# STM32MP21_CM33 register map
File version: 0.4
CPU: CM33 r0p1, little endian, MPU, FPU, vendor SysTick, 8 interrupt priority bits
Registers are 32-bit, read-write, reset 0x0 unless marked. A register's access mark holds for its fields unless they carry their own. Offsets are from the block's base; [hi:lo] are bit positions; {n}, {i} and the like mark numbered series; 'fields as' and 'values as' point back to an identical list.

## TIM12 — TIM12 address block description
Base 0x40060000
Same registers: TIM12_S 0x50060000
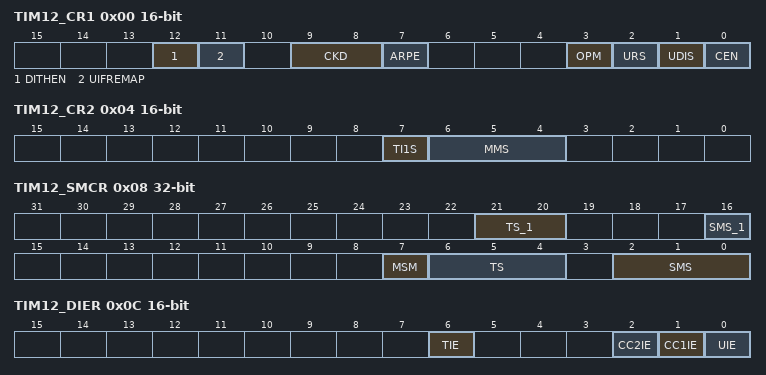
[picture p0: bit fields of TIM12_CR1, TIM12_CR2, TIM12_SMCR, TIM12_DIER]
0x00 TIM12_CR1 16-bit — TIM12 control register 1
  [12] DITHEN — Dithering enable
    0=Dithering disabled; 1=Dithering enabled
  [11] UIFREMAP — UIF status bit remapping
    0=No remapping; 1=Remapping enabled
  [9:8] CKD — Clock division
    0=tless thansub>DTSless than/sub> = tless thansub>tim_ker_ckless than/sub>; 1=tless thansub>DTSless than/sub> = 2 x tless thansub>tim_ker_ckless than/sub>; 2=tless thansub>DTSless than/sub> = 4 x tless thansub>tim_ker_ckless than/sub>
  [7] ARPE — Auto-reload preload enable
    0=TIMx_ARR register is not buffered; 1=TIMx_ARR register is buffered
  [3] OPM — One-pulse mode
    0=Counter is not stopped on the update event; 1=Counter stops counting on the next update event (clearing the CEN bit)
  [2] URS — Update request source
    0=Any of the following events generates an update interrupt if enabled; 1=Only counter overflow generates an update interrupt if enabled
  [1] UDIS — Update disable
    0=UEV enabled; 1=UEV disabled
  [0] CEN — Counter enable
    0=Counter disabled; 1=Counter enabled
0x04 TIM12_CR2 16-bit — TIM12 control register 2
  [7] TI1S — tim_ti1 selection
    0=The tim_ti1_in[15:0] multiplexer output is connected to tim_ti1 input; 1=The tim_ti1_in[15:0] and tim_ti2_in[15:0] multiplexers output are connected to the tim_ti1 input (XOR combination)
  [6:4] MMS — Master mode selection
    0=Reset - the UG bit from the TIMx_EGR register is used as trigger output (tim_trgo); 1=Enable - the Counter Enable signal CNT_EN is used as trigger output (tim_trgo); 2=Update - The update event is selected as trigger output (tim_trgo); 3=Compare Pulse - The trigger output send a positive pulse when the CC1IF flag is to be set (even if it was already high), as soon as a capture or a compare match occurred (tim_trgo); 4=Compare - tim_oc1refc signal is used as trigger output (tim_trgo); 5=Compare - tim_oc2refc signal is used as trigger output (tim_trgo)
0x08 TIM12_SMCR — TIM12 slave mode control register
  [21:20] TS_1 — TS[4:3]
  [16] SMS_1 — SMS[3]
  [7] MSM — Master/Slave mode
    0=No action; 1=The effect of an event on the trigger input (tim_trgi) is delayed to allow a perfect synchronization between the current timer and its slaves (through tim_trgo)
  [6:4] TS — TS[2:0]: Trigger selection
    {v}=Internal Trigger {v} (tim_itr{v}) (v=0..3); 4=tim_ti1 Edge Detector (tim_ti1f_ed); 5=Filtered Timer Input 1 (tim_ti1fp1); 6=Filtered Timer Input 2 (tim_ti2fp2)
  [2:0] SMS — SMS[2:0]: Slave mode selection
    0=Slave mode disabled - if CEN = 1' then the prescaler is clocked directly by the internal clock; 4=Reset Mode - Rising edge of the selected trigger input (tim_trgi) reinitializes the counter and generates an update of the registers; 5=Gated Mode - The counter clock is enabled when the trigger input (tim_trgi) is high; 6=Trigger Mode - The counter starts at a rising edge of the trigger tim_trgi (but it is not reset); 7=External Clock Mode 1 - Rising edges of the selected trigger (tim_trgi) clock the counter
0x0C TIM12_DIER 16-bit — TIM12 Interrupt enable register
  [6] TIE — Trigger interrupt enable
    0=Trigger interrupt disabled; 1=Trigger interrupt enabled
  [2] CC2IE — Capture/Compare 2 interrupt enable
    0=CC2 interrupt disabled; 1=CC2 interrupt enabled
  [1] CC1IE — Capture/Compare 1 interrupt enable
    0=CC1 interrupt disabled; 1=CC1 interrupt enabled
  [0] UIE — Update interrupt enable
    0=Update interrupt disabled; 1=Update interrupt enabled
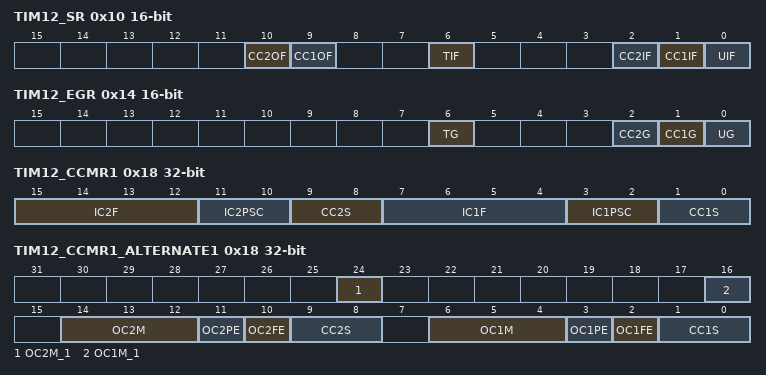
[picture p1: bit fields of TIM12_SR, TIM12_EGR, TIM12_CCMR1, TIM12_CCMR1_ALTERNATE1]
0x10 TIM12_SR 16-bit — TIM12 status register
  [10] CC2OF — Capture/compare 2 overcapture flag
  [9] CC1OF — Capture/Compare 1 overcapture flag
    0=No overcapture has been detected; 1=The counter value has been captured in TIMx_CCR1 register while CC1IF flag was already set
  [6] TIF — Trigger interrupt flag
    0=No trigger event occurred; 1=Trigger interrupt pending
  [2] CC2IF — Capture/Compare 2 interrupt flag
  [1] CC1IF — Capture/compare 1 interrupt flag
    0=No compare match / No input capture occurred; 1=A compare match or an input capture occurred
  [0] UIF — Update interrupt flag
    0=No update occurred; 1=Update interrupt pending
0x14 TIM12_EGR 16-bit wo — TIM12 event generation register
  [6] TG — Trigger generation
    0=No action; 1=The TIF flag is set in the TIMx_SR register
  [2] CC2G — Capture/compare 2 generation
  [1] CC1G — Capture/compare 1 generation
    0=No action; 1=A capture/compare event is generated on channel 1:
  [0] UG — Update generation
    0=No action; 1=Re-initializes the counter and generates an update of the registers
0x18 TIM12_CCMR1 — TIM12 capture/compare mode register 1
  [15:12] IC2F — Input capture 2 filter
  [11:10] IC2PSC — Input capture 2 prescaler
  [9:8] CC2S — Capture/compare 2 selection
    0=CC2 channel is configured as output; 1=CC2 channel is configured as input, IC2 is mapped on tim_ti2; 2=CC2 channel is configured as input, IC2 is mapped on tim_ti1; 3=CC2 channel is configured as input, IC2 is mapped on tim_trc
  [7:4] IC1F — Input capture 1 filter
    0=No filter, sampling is done at fless thansub>DTSless than/sub>; 1=fless thansub>SAMPLINGless than/sub>=fless thansub>tim_ker_ckless than/sub>, N=2; 2=fless thansub>SAMPLINGless than/sub>=fless thansub>tim_ker_ckless than/sub>, N=4; 3=fless thansub>SAMPLINGless than/sub>=fless thansub>tim_ker_ckless than/sub>, N=8; 4=fless thansub>SAMPLINGless than/sub>=fless thansub>DTSless than/sub>/2, N=6; 5=fless thansub>SAMPLINGless than/sub>=fless thansub>DTSless than/sub>/2, N=8; 6=fless thansub>SAMPLINGless than/sub>=fless thansub>DTSless than/sub>/4, N=6; 7=fless thansub>SAMPLINGless than/sub>=fless thansub>DTSless than/sub>/4, N=8; 8=fless thansub>SAMPLINGless than/sub>=fless thansub>DTSless than/sub>/8, N=6; 9=fless thansub>SAMPLINGless than/sub>=fless thansub>DTSless than/sub>/8, N=8; 10=fless thansub>SAMPLINGless than/sub>=fless thansub>DTSless than/sub>/16, N=5; 11=fless thansub>SAMPLINGless than/sub>=fless thansub>DTSless than/sub>/16, N=6; 12=fless thansub>SAMPLINGless than/sub>=fless thansub>DTSless than/sub>/16, N=8; 13=fless thansub>SAMPLINGless than/sub>=fless thansub>DTSless than/sub>/32, N=5; 14=fless thansub>SAMPLINGless than/sub>=fless thansub>DTSless than/sub>/32, N=6; 15=fless thansub>SAMPLINGless than/sub>=fless thansub>DTSless than/sub>/32, N=8
  [3:2] IC1PSC — Input capture 1 prescaler
    0=no prescaler, capture is done each time an edge is detected on the capture input; 1=capture is done once every 2 events; 2=capture is done once every 4 events; 3=capture is done once every 8 events
  [1:0] CC1S — Capture/Compare 1 selection
    0=CC1 channel is configured as output; 1=CC1 channel is configured as input, tim_ic1 is mapped on tim_ti1; 2=CC1 channel is configured as input, tim_ic1 is mapped on tim_ti2; 3=CC1 channel is configured as input, tim_ic1 is mapped on tim_trc
0x18 TIM12_CCMR1_ALTERNATE1 (alternate view of TIM12_CCMR1) — TIM12 capture/compare mode register 1
  [24] OC2M_1 — OC2M[3]
  [16] OC1M_1 — OC1M[3]
  [14:12] OC2M — OC2M[2:0]: Output compare 2 mode
  [11] OC2PE — Output compare 2 preload enable
  [10] OC2FE — Output compare 2 fast enable
  [9:8] CC2S — Capture/Compare 2 selection
    values as TIM12_CCMR1.CC2S
  [6:4] OC1M — OC1M[2:0]: Output compare 1 mode (refer to bit 16 for OC1M[3])
    0=Frozen - The comparison between the output compare register TIMx_CCR1 and the counter TIMx_CNT has no effect on the outputs; 1=Set channel 1 to active level on match; 2=Set channel 1 to inactive level on match; 3=Toggle - tim_oc1ref toggles when TIMx_CNT=TIMx_CCR1; 4=Force inactive level - tim_oc1ref is forced low; 5=Force active level - tim_oc1ref is forced high; 6=PWM mode 1 - channel 1 is active as long as TIMx_CNTless thanTIMx_CCR1 else it is inactive; 7=PWM mode 2 - channel 1 is inactive as long as TIMx_CNTless thanTIMx_CCR1 else it is active
  [3] OC1PE — Output compare 1 preload enable
    0=Preload register on TIMx_CCR1 disabled; 1=Preload register on TIMx_CCR1 enabled
  [2] OC1FE — Output compare 1 fast enable
    0=CC1 behaves normally depending on the counter and CCR1 values even when the trigger is ON; 1=An active edge on the trigger input acts like a compare match on the CC1 output
  [1:0] CC1S — Capture/Compare 1 selection
    values as TIM12_CCMR1.CC1S
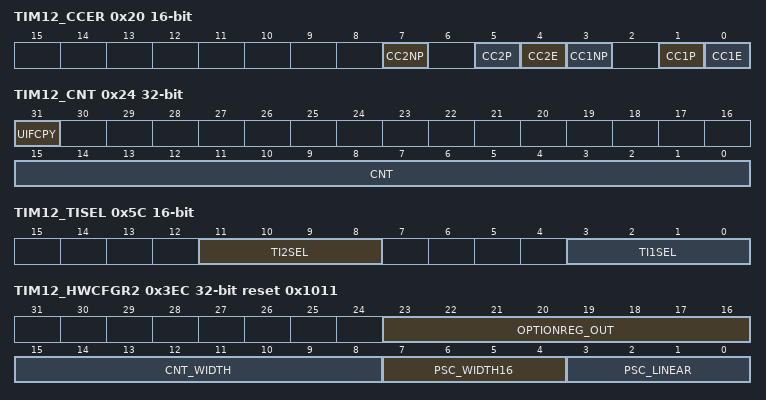
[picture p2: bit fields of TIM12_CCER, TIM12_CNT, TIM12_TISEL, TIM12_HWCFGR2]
0x20 TIM12_CCER 16-bit — TIM12 capture/compare enable register
  [7] CC2NP — Capture/Compare 2 output Polarity
  [5] CC2P — Capture/Compare 2 output Polarity
  [4] CC2E — Capture/Compare 2 output enable
  [3] CC1NP — Capture/Compare 1 complementary output Polarity
  [1] CC1P — Capture/Compare 1 output Polarity.
    0=tim_oc1 active high (output mode) / Edge sensitivity selection (input mode, see below); 1=tim_oc1 active low (output mode) / Edge sensitivity selection (input mode, see below)
  [0] CC1E — Capture/Compare 1 output enable.
    0=Capture mode disabled / tim_oc1 is not active; 1=Capture mode enabled / tim_oc1 signal is output on the corresponding output pin
0x24 TIM12_CNT — TIM12 counter
  [31] UIFCPY — UIF Copy
  [15:0] CNT — Counter value
0x28 TIM12_PSC 16-bit — TIM12 prescaler
  [15:0] PSC — Prescaler value
0x2C TIM12_ARR reset 0xFFFF — TIM12 auto-reload register
  [19:0] ARR — Auto-reload value
0x34 TIM12_CCR1 — TIM12 capture/compare register 1
  [19:0] CCR1 — Capture/compare 1 value
0x38 TIM12_CCR2 — TIM12 capture/compare register 2
  [19:0] CCR2 — Capture/compare 2 value
0x5C TIM12_TISEL 16-bit — TIM12 timer input selection register
  [11:8] TI2SEL — selects tim_ti2_in[15:0] input
    0=TIMx_CH2 input (tim_ti2_in0); 1=tim_ti2_in1; 4=tim_ti2_in15
  [3:0] TI1SEL — selects tim_ti1_in[15:0] input
    0=TIMx_CH1 input (tim_ti1_in0); 1=tim_ti1_in1; 15=tim_ti1_in15
0x3EC TIM12_HWCFGR2 ro reset 0x1011 — TIM12 hardware configuration 2 register
  [23:16] OPTIONREG_OUT — Option register number (0 to 16).
  [15:8] CNT_WIDTH — Counter width
    8=8-bits; 16=16-bits; 32=32-bits
  [7:4] PSC_WIDTH16 — Prescaler width
    0=7 (by power of 2) /8 (linear) -bit counter; 1=15 (by power of 2) /16 (linear) -bit counter
  [3:0] PSC_LINEAR — Prescaler linear
    0=prescaler by power of 2 (division by 1, 2, 4, 8; 1=prescaler is linear (division by 1, 2, 3, 4, 5
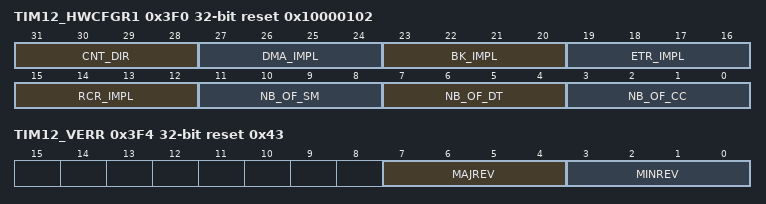
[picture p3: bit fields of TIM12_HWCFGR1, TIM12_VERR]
0x3F0 TIM12_HWCFGR1 ro reset 0x10000102 — TIM12 hardware configuration 1 register
  [31:28] CNT_DIR — Counter direction
    0=Down-counter only; 1=Up-counter only; 2=Up/Down counter allowing center-aligned mode
  [27:24] DMA_IMPL — DMA features implementation
    0=DMA requests are not possible; 1=Single DMA requests possible; 2=All DMA features implemented
  [23:20] BK_IMPL — Break circuit implementation
    0=no break implemented; 1=break1 implemented without filter (tim_brk + tim_sys_brk connected); 2=break1 implemented with filter (tim_brk + tim_sys_brk connected); 3=break 1 and 2 implemented (tim_brk + tim_sys_brk + brk2)
  [19:16] ETR_IMPL — External trigger implementation
    0=External trigger circuit not implemented, ocrefx cleared by ocref_clr input; 1=External trigger circuit implemented, ocrefx cleared by ocref_clr input; 2=External trigger circuit implemented, ocrefx cleared by etrf signal; 3=External trigger circuit implemented, ocrefx cleared by ocref_clr or etrf (1 control bit OCCS added in GPT_SMCR)
  [15:12] RCR_IMPL — Repetition counter implementation
    0=repetition counter not implemented; 1=8-bit repetition counter implemented; 2=16-bit repetition counter implemented
  [11:8] NB_OF_SM — Number of synchronization module
    0=synchronization module not implemented; 1=1 synchronization module implemented
  [7:4] NB_OF_DT — Number of complementary outputs and dead-time generators
  [3:0] NB_OF_CC — Number of capture / compare channel
    0=no capture/compare channel implemented; 1=only CC1 channel is implemented; 2=CC1 and CC2 channels are implemented; 3=CC1, CC2 and CC3 channels are implemented; 4=CC1, CC2, CC3 and CC4 channels are implemented; 5=CC1, CC2, CC3, CC4 and CC5 channels are implemented; 6=CC1, CC2, CC3, CC4, CC5 and CC6 channels are implemented
0x3F4 TIM12_VERR ro reset 0x43 — TIM12 IP version register
  [7:4] MAJREV — Major revision number.
  [3:0] MINREV — Minor revision number.
0x3F8 TIM12_IPIDR ro reset 0x120002 — TIM12 IP identification register
  [31:0] ID — IP identification code.
0x3FC TIM12_SIDR ro reset 0xA3C5DD01 — TIM12 size ID register
  [31:0] SID — Offset in KB of the ID register base address from the IP base address.
    1=1KB offset
